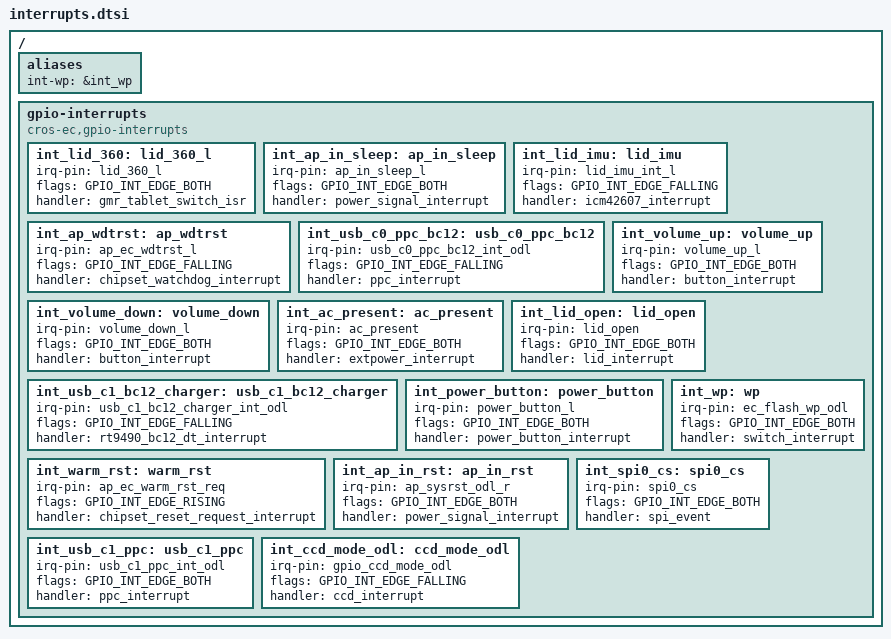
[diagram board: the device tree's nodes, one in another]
/* Copyright 2022 The ChromiumOS Authors
 * Use of this source code is governed by a BSD-style license that can be
 * found in the LICENSE file.
 */

/ {
	aliases {
		int-wp = &int_wp;
	};

	gpio-interrupts {
		compatible = "cros-ec,gpio-interrupts";

		int_lid_360: lid_360_l {
			irq-pin = <&lid_360_l>;
			flags = <GPIO_INT_EDGE_BOTH>;
			handler = "gmr_tablet_switch_isr";
		};
		int_ap_in_sleep: ap_in_sleep {
			irq-pin = <&ap_in_sleep_l>;
			flags = <GPIO_INT_EDGE_BOTH>;
			handler = "power_signal_interrupt";
		};
		int_lid_imu: lid_imu {
			irq-pin = <&lid_imu_int_l>;
			flags = <GPIO_INT_EDGE_FALLING>;
			handler = "icm42607_interrupt";
		};
		int_ap_wdtrst: ap_wdtrst {
			irq-pin = <&ap_ec_wdtrst_l>;
			flags = <GPIO_INT_EDGE_FALLING>;
			handler = "chipset_watchdog_interrupt";
		};
		int_usb_c0_ppc_bc12: usb_c0_ppc_bc12 {
			irq-pin = <&usb_c0_ppc_bc12_int_odl>;
			flags = <GPIO_INT_EDGE_FALLING>;
			handler = "ppc_interrupt";
		};
		int_volume_up: volume_up {
			irq-pin = <&volume_up_l>;
			flags = <GPIO_INT_EDGE_BOTH>;
			handler = "button_interrupt";
		};
		int_volume_down: volume_down {
			irq-pin = <&volume_down_l>;
			flags = <GPIO_INT_EDGE_BOTH>;
			handler = "button_interrupt";
		};
		int_ac_present: ac_present {
			irq-pin = <&ac_present>;
			flags = <GPIO_INT_EDGE_BOTH>;
			handler = "extpower_interrupt";
		};
		int_usb_c1_bc12_charger: usb_c1_bc12_charger {
			irq-pin = <&usb_c1_bc12_charger_int_odl>;
			flags = <GPIO_INT_EDGE_FALLING>;
			handler = "rt9490_bc12_dt_interrupt";
		};
		int_lid_open: lid_open {
			irq-pin = <&lid_open>;
			flags = <GPIO_INT_EDGE_BOTH>;
			handler = "lid_interrupt";
		};
		int_power_button: power_button {
			irq-pin = <&power_button_l>;
			flags = <GPIO_INT_EDGE_BOTH>;
			handler = "power_button_interrupt";
		};
		int_warm_rst: warm_rst {
			irq-pin = <&ap_ec_warm_rst_req>;
			flags = <GPIO_INT_EDGE_RISING>;
			handler = "chipset_reset_request_interrupt";
		};
		int_ap_in_rst: ap_in_rst {
			irq-pin = <&ap_sysrst_odl_r>;
			flags = <GPIO_INT_EDGE_BOTH>;
			handler = "power_signal_interrupt";
		};
		int_wp: wp {
			irq-pin = <&ec_flash_wp_odl>;
			flags = <GPIO_INT_EDGE_BOTH>;
			handler = "switch_interrupt";
		};
		int_spi0_cs: spi0_cs {
			irq-pin = <&spi0_cs>;
			flags = <GPIO_INT_EDGE_BOTH>;
			handler = "spi_event";
		};
		int_usb_c1_ppc: usb_c1_ppc {
			irq-pin = <&usb_c1_ppc_int_odl>;
			flags = <GPIO_INT_EDGE_BOTH>;
			handler = "ppc_interrupt";
		};
		int_ccd_mode_odl: ccd_mode_odl {
			irq-pin = <&gpio_ccd_mode_odl>;
			flags = <GPIO_INT_EDGE_FALLING>;
			handler = "ccd_interrupt";
		};
	};
};
